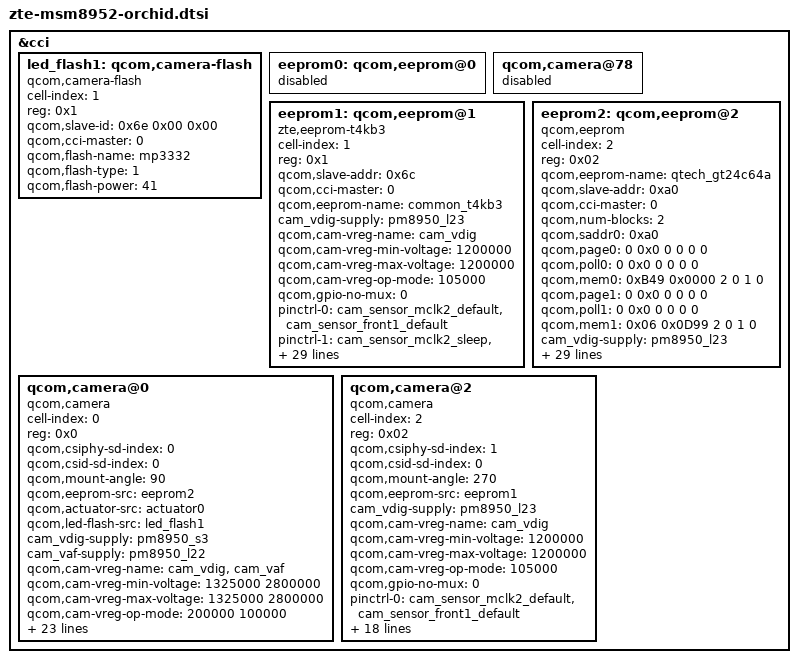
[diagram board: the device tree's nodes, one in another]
/* Copyright (c) 2014-2015, The Linux Foundation. All rights reserved.
 *
 * This program is free software; you can redistribute it and/or modify
 * it under the terms of the GNU General Public License version 2 and
 * only version 2 as published by the Free Software Foundation.
 *
 */
 #include "touch-key-backlight-orchid.dtsi"
 #include "zte-msm8952-ext-codec.dtsi"
 
&cci {

	led_flash1: qcom,camera-flash  {
		cell-index = <1>;
		reg = <0x1>;
		qcom,slave-id = <0x6e 0x00 0x00>;
		compatible = "qcom,camera-flash";
		qcom,cci-master = <0>;
		qcom,flash-name = "mp3332";
		qcom,flash-type = <1>;
		qcom,flash-power = <41>;
		status = "ok";
	};

	//disable eeprom 0 for orchid,it will cause eeprom reading time too long ZTE_CAM_LIJING_20151012
	eeprom0: qcom,eeprom@0 {
		status = "disabled";
	};

	qcom,camera@78 {
		status = "disabled";
	};

	eeprom1: qcom,eeprom@1 {
		compatible = "zte,eeprom-t4kb3";
		cell-index = <1>;
		reg = <0x1>;
		qcom,slave-addr = <0x6c>;
		qcom,cci-master = <0>;
		qcom,eeprom-name = "common_t4kb3";
		cam_vdig-supply = <&pm8950_l23>;		
		qcom,cam-vreg-name = "cam_vdig";
		qcom,cam-vreg-min-voltage = <1200000>;
		qcom,cam-vreg-max-voltage = <1200000>;
		qcom,cam-vreg-op-mode = <105000>;
		qcom,gpio-no-mux = <0>;
		pinctrl-names = "cam_default", "cam_suspend";
		pinctrl-0 = <&cam_sensor_mclk2_default &cam_sensor_front1_default>;
		pinctrl-1 = <&cam_sensor_mclk2_sleep &cam_sensor_front1_sleep>;

		gpios = <&msm_gpio 28 0>,
			<&msm_gpio 40 0>,
			<&msm_gpio 39 0>,
			<&msm_gpio 41 0>,
			<&msm_gpio 89 0>;
		qcom,gpio-reset = <1>;
		qcom,gpio-standby = <2>;
		qcom,gpio-vio = <3>;
		qcom,gpio-vana = <4>;
		qcom,gpio-req-tbl-num = <0 1 2 3 4>;
		qcom,gpio-req-tbl-flags = <1 0 0 0 0>;
		qcom,gpio-req-tbl-label = "CAMIF_MCLK2",
					  "CAM_RESET2",
					  "CAM_STANDBY2",
					  "CAM_VIO2",
			               "CAM_VANA2";
		qcom,cam-power-seq-type = "sensor_gpio",
								     "sensor_gpio",
								     "sensor_gpio",
								     "sensor_vreg",
								     "sensor_gpio",
								     "sensor_clk",
								     "sensor_gpio",
								     "sensor_gpio",
								     "sensor_i2c_mux";
		qcom,cam-power-seq-val = "sensor_gpio_reset",
								   "sensor_gpio_standby",
								    "sensor_gpio_vio",
								    "cam_vdig",
								   "sensor_gpio_vana",
								    "sensor_cam_mclk",
								    "sensor_gpio_reset",
								   "sensor_gpio_standby",
								   "none";						 
		qcom,cam-power-seq-cfg-val = < 0 0   1 1 1 24000000  1 1 0>;
		qcom,cam-power-seq-delay =   < 0 2   0 3 3  2              3 3 0>;
		zte,num-blocks = <3>;
		zte,mem0    = <64	 0 2 0x0 1 0>;	
		zte,mem1    = <64	 0 2 0x0 1 0>;  
		zte,mem2    = <64	 0 2 0x0 1 0>;  
		clocks = <&clock_gcc clk_mclk2_clk_src>,
			<&clock_gcc clk_gcc_camss_mclk2_clk>;
		clock-names = "cam_src_clk", "cam_clk";
		status = "ok";
		
	};

	eeprom2: qcom,eeprom@2{
		cell-index = <2>;
		reg = <0x02>;
		qcom,eeprom-name = "qtech_gt24c64a";
		compatible = "qcom,eeprom";
		qcom,slave-addr = <0xa0>;
		qcom,cci-master = <0>;
		qcom,num-blocks = <2>;

		qcom,saddr0 = <0xa0>;
		qcom,page0 = <0 0x0 0 0 0 0>;
		qcom,poll0 = <0 0x0 0 0 0 0>;
		qcom,mem0 = <0xB49 0x0000 2 0 1 0>;

		qcom,page1 = <0 0x0 0 0 0 0>;
		qcom,poll1 = <0 0x0 0 0 0 0>;
		qcom,mem1 = <0x06 0x0D99 2 0 1 0>;

		cam_vdig-supply = <&pm8950_l23>;
		cam_vana-supply = <&pm8950_l22>;
		cam_vio-supply = <&pm8950_l6>;
		qcom,i2c-freq-mode = <1>;
		qcom,cam-vreg-name = "cam_vdig", "cam_vio", "cam_vana";
		qcom,cam-vreg-min-voltage = <1200000 0 2800000>;
		qcom,cam-vreg-max-voltage = <1200000 0 2800000>;
		qcom,cam-vreg-op-mode = <200000 0 80000>;
		pinctrl-names = "cam_default", "cam_suspend";
		pinctrl-0 = <&cam_sensor_mclk0_default &cam_sensor_rear_default>;
		pinctrl-1 = <&cam_sensor_mclk0_sleep &cam_sensor_rear_sleep>;
		gpios = <&msm_gpio 26 0>,
			<&msm_gpio 36 0>,
			<&msm_gpio 35 0>;
		qcom,gpio-reset = <1>;
		qcom,gpio-standby = <2>;
		qcom,gpio-req-tbl-num = <0 1 2>;
		qcom,gpio-req-tbl-flags = <1 0 0>;
		qcom,gpio-req-tbl-label = "CAMIF_MCLK0",
			"MCAM_RESET0",
			"MCAM_STANDBY0";
		qcom,cam-power-seq-type = "sensor_vreg",
		"sensor_vreg", "sensor_vreg",
			"sensor_clk",
			"sensor_gpio", "sensor_gpio";
		qcom,cam-power-seq-val = "cam_vio",
			"cam_vana", "cam_vdig",
			"sensor_cam_mclk",
			"sensor_gpio_reset",
			"sensor_gpio_standby";
		qcom,cam-power-seq-cfg-val = <1 1 1 24000000 1 1>;
		qcom,cam-power-seq-delay = <1 1 5 5 5 10>;
		status = "ok";
		clocks = <&clock_gcc clk_mclk0_clk_src>,
				<&clock_gcc clk_gcc_camss_mclk0_clk>;
		clock-names = "cam_src_clk", "cam_clk";
	};
	
	/* CAMERA_POSITION_REAR*/
	qcom,camera@0 {
		cell-index = <0>;
		compatible = "qcom,camera";
		reg = <0x0>;
		qcom,csiphy-sd-index = <0>;
		qcom,csid-sd-index = <0>;
		qcom,mount-angle = <90>;
		qcom,eeprom-src = <&eeprom2>;
		qcom,actuator-src = <&actuator0>;
		qcom,led-flash-src = <&led_flash1>;
		cam_vdig-supply = <&pm8950_s3>;
		cam_vaf-supply = <&pm8950_l22>;
		qcom,cam-vreg-name = "cam_vdig", "cam_vaf";
		qcom,cam-vreg-min-voltage = <1325000  2800000>;
		qcom,cam-vreg-max-voltage = <1325000  2800000>;
		qcom,cam-vreg-op-mode = <200000  100000>;
		pinctrl-names = "cam_default", "cam_suspend";
		pinctrl-0 = <&cam_sensor_mclk0_default
				&cam_sensor_rear_default>;
		pinctrl-1 = <&cam_sensor_mclk0_sleep &cam_sensor_rear_sleep>;
		gpios = <&msm_gpio 26 0>,
			<&msm_gpio 36 0>,
			<&msm_gpio 35 0>,
			<&msm_gpio 41 0>,
			<&msm_gpio 132 0>,
			<&msm_gpio 131 0>,
		       <&msm_gpio 34 0>;
		qcom,gpio-reset = <1>;
		qcom,gpio-standby = <2>;
		qcom,gpio-vio = <3>;
		qcom,gpio-vdig = <4>;
		qcom,gpio-vana = <5>;
		qcom,gpio-flash-now = <6>;
		qcom,gpio-req-tbl-num = <0 1 2 3 4 5 6 >;
		qcom,gpio-req-tbl-flags = <1 0 0 0 0 0  0>;
		qcom,gpio-req-tbl-label = "CAMIF_MCLK0",
			"CAM_RESET0",
			"CAM_STANDBY0",
			"CAM_VIO0",
			"CAM_VDIG0",
			"CAM_VANA0",
		       "CAM_FLASH";
		qcom,sensor-position = <0>;/*0 means CAMERA_POSITION_BACK*/
		qcom,sensor-mode = <0>;
		qcom,cci-master = <0>;
		status = "ok";
		clocks = <&clock_gcc clk_mclk0_clk_src>,
				<&clock_gcc clk_gcc_camss_mclk0_clk>;
		clock-names = "cam_src_clk", "cam_clk";
	};

	/* CAMERA_POSITION_FRONT */
	qcom,camera@2 {
		cell-index = <2>;
		compatible = "qcom,camera";
		reg = <0x02>;
		qcom,csiphy-sd-index = <1>;
		qcom,csid-sd-index = <0>;
		qcom,mount-angle = <270>;
		qcom,eeprom-src = <&eeprom1>;
		cam_vdig-supply = <&pm8950_l23>;
		qcom,cam-vreg-name = "cam_vdig";
		qcom,cam-vreg-min-voltage = <1200000>;
		qcom,cam-vreg-max-voltage = <1200000>;
		qcom,cam-vreg-op-mode = <105000>;
		qcom,gpio-no-mux = <0>;
		pinctrl-names = "cam_default", "cam_suspend";
		pinctrl-0 = <&cam_sensor_mclk2_default &cam_sensor_front1_default>;
		pinctrl-1 = <&cam_sensor_mclk2_sleep &cam_sensor_front1_sleep>;
		gpios = <&msm_gpio 28 0>,
			<&msm_gpio 40 0>,
			<&msm_gpio 39 0>,
			<&msm_gpio 41 0>,
			<&msm_gpio 89 0>;
		qcom,gpio-reset = <1>;
		qcom,gpio-standby = <2>;
		qcom,gpio-vio = <3>;
		qcom,gpio-vana = <4>;
		qcom,gpio-req-tbl-num = <0 1 2 3 4>;
		qcom,gpio-req-tbl-flags = <1 0 0 0 0>;
		qcom,gpio-req-tbl-label = "CAMIF_MCLK2",
					  "CAM_RESET2",
					  "CAM_STANDBY2",
					  "CAM_VIO2",
			      "CAM_VANA2";
		qcom,sensor-position = <1>;/*1 means CAMERA_POSITION_FRONT*/
		qcom,sensor-mode = <1>;
		qcom,cci-master = <0>;
		status = "ok";
		clocks = <&clock_gcc clk_mclk2_clk_src>,
			<&clock_gcc clk_gcc_camss_mclk2_clk>;
		clock-names = "cam_src_clk", "cam_clk";
	};
};
